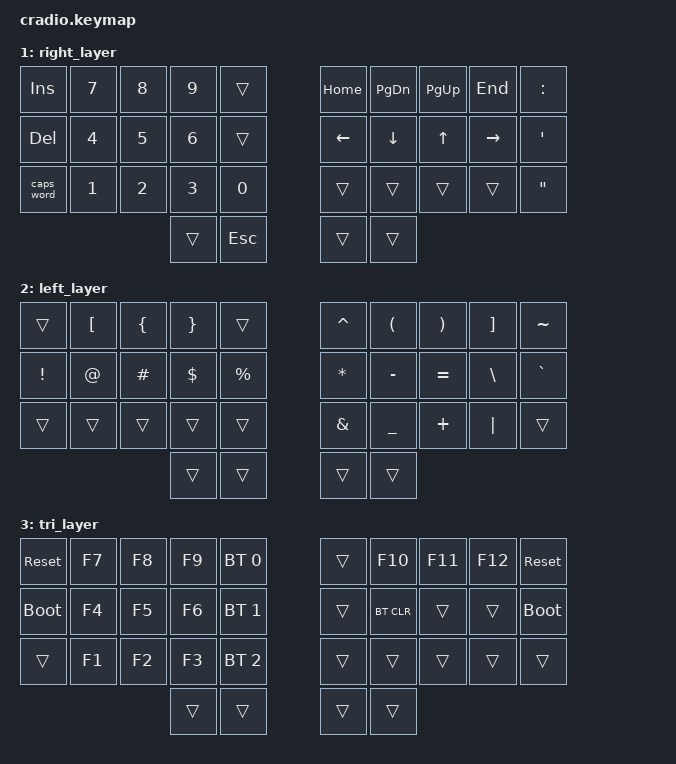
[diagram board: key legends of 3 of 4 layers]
// Copyright (c) 2022 The ZMK Contributors
// SPDX-License-Identifier: MIT

#include <behaviors.dtsi>
#include <dt-bindings/zmk/keys.h>
#include <dt-bindings/zmk/bt.h>

// Home row mods macro
#define HRML(k1,k2,k3,k4) &ht LSHFT k1  &ht LALT k2  &ht LCTRL k3  &ht LGUI k4
#define HRMR(k1,k2,k3,k4) &ht RGUI k1  &ht RCTRL k2  &ht RALT k3  &ht RSHFT k4

/ {
    behaviors {
        ht: hold_tap {
            compatible = "zmk,behavior-hold-tap";
            #binding-cells = <2>;
            flavor = "tap-preferred";
            tapping-term-ms = <220>;
            quick-tap-ms = <150>;
            require-prior-idle-ms = <100>;
            bindings = <&kp>, <&kp>;
        };
    };

    conditional_layers {
        compatible = "zmk,conditional-layers";
        tri_layer {
            if-layers = <1 2>;
            then-layer = <3>;
        };
    };

    keymap {
        compatible = "zmk,keymap";
        default_layer {
            bindings = <
             &kp Q     &kp W      &kp E     &kp R      &kp T    &kp Y  &kp U        &kp I        &kp O           &kp P
            HRML(A,        S,         D,        F)     &kp G          &kp H      HRMR(J,        K,         L,        SEMI)
            &kp Z      &kp X      &kp C     &kp V      &kp B          &kp N      &kp M      &kp COMMA  &kp DOT    &kp FSLH
                                            &lt 2 TAB  &kp BSPC     &kp SPACE  &lt 1 ENTER
            >;
        };

        right_layer {
            bindings = <
            &kp INS    &kp N7     &kp N8     &kp N9     &trans         &kp HOME   &kp PG_DN  &kp PG_UP  &kp END    &kp COLON
            &kp DEL    &kp N4     &kp N5     &kp N6     &trans         &kp LEFT   &kp DOWN   &kp UP   &kp RIGHT   &kp SQT
           &caps_word  &kp N1     &kp N2     &kp N3     &kp N0         &trans     &trans     &trans     &trans     &kp DQT
                                             &trans     &kp ESC        &trans     &trans
            >;
        };

        left_layer {
            bindings = <
            &trans     &kp LBKT   &kp LBRC   &kp RBRC   &trans         &kp CARET  &kp LPAR   &kp RPAR   &kp RBKT   &kp TILDE
            &kp EXCL   &kp AT     &kp HASH   &kp DLLR   &kp PRCNT      &kp ASTRK  &kp MINUS  &kp EQUAL  &kp BSLH   &kp GRAVE
            &trans     &trans     &trans     &trans     &trans         &kp AMPS   &kp UNDER  &kp PLUS   &kp PIPE   &trans
                                             &trans     &trans         &trans     &trans
            >;
        };

        tri_layer {
            bindings = <
           &sys_reset  &kp F7     &kp F8     &kp F9    &bt BT_SEL 0    &trans     &kp F10    &kp F11   &kp F12     &sys_reset
          &bootloader  &kp F4     &kp F5     &kp F6    &bt BT_SEL 1    &trans     &bt BT_CLR &trans     &trans    &bootloader
            &trans     &kp F1     &kp F2    &kp F3    &bt BT_SEL 2    &trans     &trans     &trans     &trans     &trans
                                             &trans     &trans         &trans     &trans
            >;
        };
    };
};
